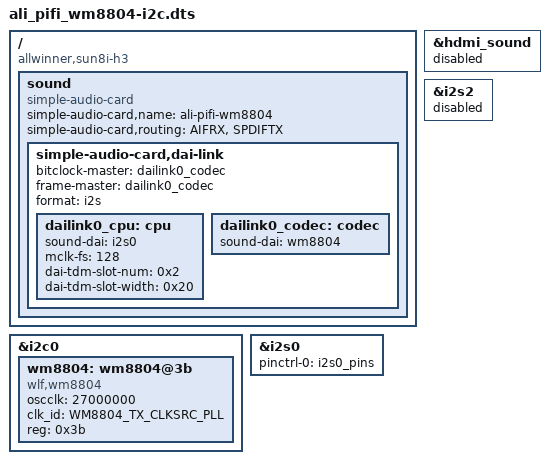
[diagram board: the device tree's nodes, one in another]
/dts-v1/;
/plugin/;

/ {
	compatible = "allwinner,sun8i-h3";

	fragment@0 {
		target = <&i2c0>;
		__overlay__ {
			#address-cells = <1>;
			#size-cells = <0>;
			wm8804: wm8804@3b {
				#sound-dai-cells = <0>;
				compatible = "wlf,wm8804";
				oscclk = <27000000>;
				clk_id = "WM8804_TX_CLKSRC_PLL";
	//			clk_id = "WM8804_TX_CLKSRC_MCLK";
	//			external_mclk; 
				reg = <0x3b>;
				status = "okay";
				// DVDD-supply = <&reg_3v3>;
				// PVDD-supply = <&reg_3v3>;
	// be aware that parameters of this node work only with patched version of wm8804.c driver 
	// done to make it work with volumio . fragment@3 and @4 made to disable hdmi sound on opi board for testing  
			};
			};
		};
	fragment@1 {
		target = <&i2s0>;
		__overlay__ {
			status = "okay";
			pinctrl-0 = <&i2s0_pins>;
			pinctrl-names = "default";
		};
	};
	
	fragment@2 {
		target-path = "/";
		__overlay__ {
			sound {
				compatible = "simple-audio-card";
				simple-audio-card,name = "ali-pifi-wm8804";
				simple-audio-card,routing =
					"AIFRX", "SPDIFTX";
				simple-audio-card,dai-link {
				bitclock-master = <&dailink0_codec>;
				frame-master = <&dailink0_codec>;
				format = "i2s";
		                status = "okay";

				dailink0_cpu: cpu {
					sound-dai = <&i2s0>;
					mclk-fs = <128>;
					dai-tdm-slot-num = < 0x2 >;
					dai-tdm-slot-width = < 0x20 >;
				};

				dailink0_codec: codec {
					sound-dai = <&wm8804>;
				//	system-clock-frequency = <27000000>;
				};
				};
			};
		};
	};
	fragment@3 {
		target = <&hdmi_sound>;
		__overlay__ {
			status = "disabled";		
	};
			};

	fragment@4 {
		target = <&i2s2>;
		__overlay__ {
			status = "disabled";		
	};
			};


};
